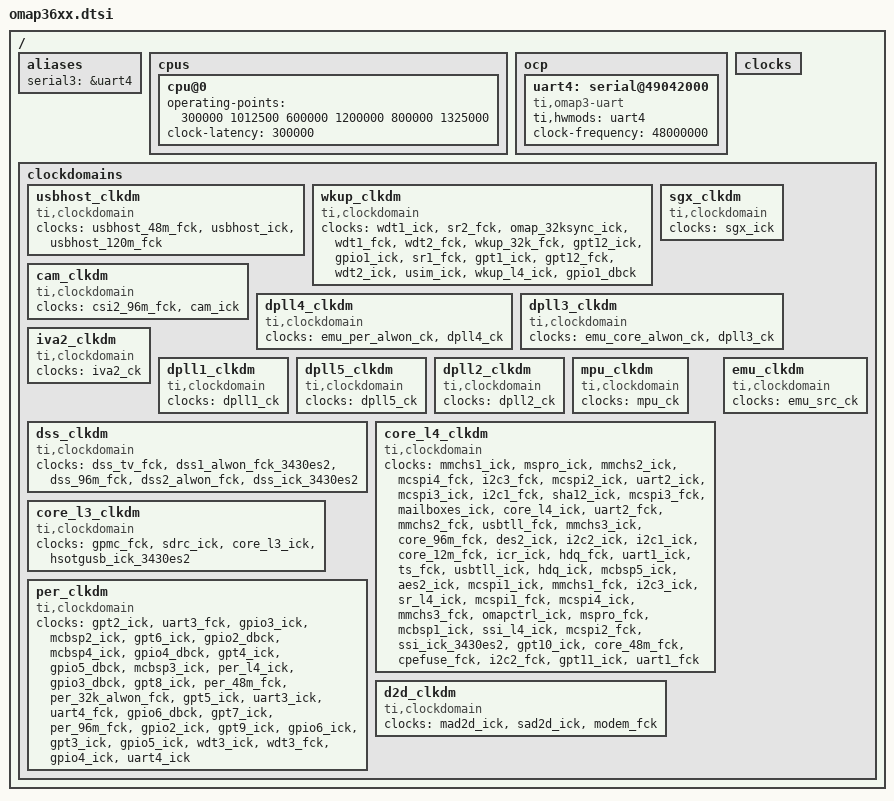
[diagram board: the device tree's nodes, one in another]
/*
 * Device Tree Source for OMAP3 SoC
 *
 * Copyright (C) 2012 Texas Instruments Incorporated - http://www.ti.com/
 *
 * This file is licensed under the terms of the GNU General Public License
 * version 2.  This program is licensed "as is" without any warranty of any
 * kind, whether express or implied.
 */

#include "omap3.dtsi"

/ {
	aliases {
		serial3 = &uart4;
	};

	cpus {
		/* OMAP3630/OMAP37xx 'standard device' variants OPP50 to OPP130 */
		cpu@0 {
			operating-points = <
				/* kHz    uV */
				300000  1012500
				600000  1200000
				800000  1325000
			>;
			clock-latency = <300000>; /* From legacy driver */
		};
	};

	ocp {
		uart4: serial@49042000 {
			compatible = "ti,omap3-uart";
			ti,hwmods = "uart4";
			clock-frequency = <48000000>;
		};
	};

	clocks {
		#address-cells = <1>;
		#size-cells = <1>;
		ranges;
		/include/ "omap36xx-clocks.dtsi"
		/include/ "omap34xx-omap36xx-clocks.dtsi"
		/include/ "omap36xx-omap3430es2plus-clocks.dtsi"
		/include/ "omap36xx-am35xx-omap3430es2plus-clocks.dtsi"
	};

	clockdomains {
		usbhost_clkdm: usbhost_clkdm {
			compatible = "ti,clockdomain";
			clocks = <&usbhost_48m_fck>, <&usbhost_ick>,
				 <&usbhost_120m_fck>;
		};

		wkup_clkdm: wkup_clkdm {
			compatible = "ti,clockdomain";
			clocks = <&wdt1_ick>, <&sr2_fck>, <&omap_32ksync_ick>,
				 <&wdt1_fck>, <&wdt2_fck>, <&wkup_32k_fck>,
				 <&gpt12_ick>, <&gpio1_ick>, <&sr1_fck>,
				 <&gpt1_ick>, <&gpt12_fck>, <&wdt2_ick>,
				 <&usim_ick>, <&wkup_l4_ick>, <&gpio1_dbck>;
		};

		cam_clkdm: cam_clkdm {
			compatible = "ti,clockdomain";
			clocks = <&csi2_96m_fck>, <&cam_ick>;
		};

		dpll4_clkdm: dpll4_clkdm {
			compatible = "ti,clockdomain";
			clocks = <&emu_per_alwon_ck>, <&dpll4_ck>;
		};

		sgx_clkdm: sgx_clkdm {
			compatible = "ti,clockdomain";
			clocks = <&sgx_ick>;
		};

		dpll3_clkdm: dpll3_clkdm {
			compatible = "ti,clockdomain";
			clocks = <&emu_core_alwon_ck>, <&dpll3_ck>;
		};

		iva2_clkdm: iva2_clkdm {
			compatible = "ti,clockdomain";
			clocks = <&iva2_ck>;
		};

		dpll1_clkdm: dpll1_clkdm {
			compatible = "ti,clockdomain";
			clocks = <&dpll1_ck>;
		};

		dpll5_clkdm: dpll5_clkdm {
			compatible = "ti,clockdomain";
			clocks = <&dpll5_ck>;
		};

		dpll2_clkdm: dpll2_clkdm {
			compatible = "ti,clockdomain";
			clocks = <&dpll2_ck>;
		};

		dss_clkdm: dss_clkdm {
			compatible = "ti,clockdomain";
			clocks = <&dss_tv_fck>, <&dss1_alwon_fck_3430es2>,
				 <&dss_96m_fck>, <&dss2_alwon_fck>,
				 <&dss_ick_3430es2>;
		};

		mpu_clkdm: mpu_clkdm {
			compatible = "ti,clockdomain";
			clocks = <&mpu_ck>;
		};

		core_l4_clkdm: core_l4_clkdm {
			compatible = "ti,clockdomain";
			clocks = <&mmchs1_ick>, <&mspro_ick>, <&mmchs2_ick>,
				 <&mcspi4_fck>, <&i2c3_fck>, <&mcspi2_ick>,
				 <&uart2_ick>, <&mcspi3_ick>, <&i2c1_fck>,
				 <&sha12_ick>, <&mcspi3_fck>, <&mailboxes_ick>,
				 <&core_l4_ick>, <&uart2_fck>, <&mmchs2_fck>,
				 <&usbtll_fck>, <&mmchs3_ick>, <&core_96m_fck>,
				 <&des2_ick>, <&i2c2_ick>, <&i2c1_ick>,
				 <&core_12m_fck>, <&icr_ick>, <&hdq_fck>,
				 <&uart1_ick>, <&ts_fck>, <&usbtll_ick>,
				 <&hdq_ick>, <&mcbsp5_ick>, <&aes2_ick>,
				 <&mcspi1_ick>, <&mmchs1_fck>, <&i2c3_ick>,
				 <&sr_l4_ick>, <&mcspi1_fck>, <&mcspi4_ick>,
				 <&mmchs3_fck>, <&omapctrl_ick>, <&mspro_fck>,
				 <&mcbsp1_ick>, <&ssi_l4_ick>, <&mcspi2_fck>,
				 <&ssi_ick_3430es2>, <&gpt10_ick>,
				 <&core_48m_fck>, <&cpefuse_fck>, <&i2c2_fck>,
				 <&gpt11_ick>, <&uart1_fck>;
		};

		core_l3_clkdm: core_l3_clkdm {
			compatible = "ti,clockdomain";
			clocks = <&gpmc_fck>, <&sdrc_ick>, <&core_l3_ick>,
				 <&hsotgusb_ick_3430es2>;
		};

		per_clkdm: per_clkdm {
			compatible = "ti,clockdomain";
			clocks = <&gpt2_ick>, <&uart3_fck>, <&gpio3_ick>,
				 <&mcbsp2_ick>, <&gpt6_ick>, <&gpio2_dbck>,
				 <&mcbsp4_ick>, <&gpio4_dbck>, <&gpt4_ick>,
				 <&gpio5_dbck>, <&mcbsp3_ick>, <&per_l4_ick>,
				 <&gpio3_dbck>, <&gpt8_ick>, <&per_48m_fck>,
				 <&per_32k_alwon_fck>, <&gpt5_ick>,
				 <&uart3_ick>, <&uart4_fck>, <&gpio6_dbck>,
				 <&gpt7_ick>, <&per_96m_fck>, <&gpio2_ick>,
				 <&gpt9_ick>, <&gpio6_ick>, <&gpt3_ick>,
				 <&gpio5_ick>, <&wdt3_ick>, <&wdt3_fck>,
				 <&gpio4_ick>, <&uart4_ick>;
		};

		emu_clkdm: emu_clkdm {
			compatible = "ti,clockdomain";
			clocks = <&emu_src_ck>;
		};

		d2d_clkdm: d2d_clkdm {
			compatible = "ti,clockdomain";
			clocks = <&mad2d_ick>, <&sad2d_ick>, <&modem_fck>;
		};
	};
};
